# RA register map
Vendor: Renesas; Series: All Chips; File version: x.xx
Registers are 32-bit, read-write, reset 0x0 unless marked. A register's access mark holds for its fields unless they carry their own. Offsets are from the block's base; [hi:lo] are bit positions; 'fields as' and 'values as' point back to an identical list.

## R_CAC — Clock Frequency Accuracy Measurement Circuit
Base 0x40044600
0x00 CACR0 8-bit — CAC Control Register 0
  [0] CFME — Clock Frequency Measurement Enable.
    0=Disable; 1=Enable
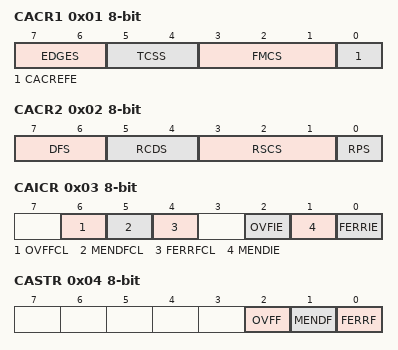
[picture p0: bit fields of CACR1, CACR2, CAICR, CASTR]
0x01 CACR1 8-bit — CAC Control Register 1
  [7:6] EDGES — Valid Edge Select
    0=Rising edge; 1=Falling edge; 2=Both rising and falling edges; 3=Setting prohibited
  [5:4] TCSS — Measurement Target Clock Frequency Division Ratio Select
    0=No division; 1=x 1/4 clock; 2=x 1/8 clock; 3=x 1/32 clock
  [3:1] FMCS — Measurement Target Clock Select
    0=Main clock; 1=Sub-clock; 2=HOCO clock; 3=MOCO clock; 4=LOCO clock; 5=Peripheral module clock(PCLKB); 6=IWDTCLK clock; 7=Setting prohibited
  [0] CACREFE — CACREF Pin Input Enable
    0=Disable; 1=Enable
0x02 CACR2 8-bit — CAC Control Register 2
  [7:6] DFS — Digital Filter Selection
    0=Digital filtering is disabled; 1=The sampling clock for the digital filter is the frequency measuring clock; 2=The sampling clock for the digital filter is the frequency measuring clock divided by 4; 3=The sampling clock for the digital filter is the frequency measuring clock divided by 16
  [5:4] RCDS — Measurement Reference Clock Frequency Division Ratio Select
    0=1/32 clock; 1=1/128 clock; 2=1/1024 clock; 3=1/8192 clock
  [3:1] RSCS — Measurement Reference Clock Select
    values as CACR1.FMCS
  [0] RPS — Reference Signal Select
    0=CACREF pin input; 1=Internal clock (internally generated signal)
0x03 CAICR 8-bit — CAC Interrupt Control Register
  [6] OVFFCL wo — OVFF Clear
    0=No effect on operations; 1=Clears the OVFF flag
  [5] MENDFCL wo — MENDF Clear
    0=No effect on operations; 1=Clears the MENDF flag
  [4] FERRFCL wo — FERRF Clear
    0=No effect on operations; 1=Clears the FERRF flag
  [2] OVFIE — Overflow Interrupt Request Enable
    0=Disable; 1=Enable
  [1] MENDIE — Measurement End Interrupt Request Enable
    0=Disable; 1=Enable
  [0] FERRIE — Frequency Error Interrupt Request Enable
    0=Disable; 1=Enable
0x04 CASTR 8-bit ro — CAC Status Register
  [2] OVFF — Counter Overflow Flag
    0=The counter has not overflowed; 1=The counter has overflowed
  [1] MENDF — Measurement End Flag
    0=Measurement is in progress; 1=Measurement has ended
  [0] FERRF — Frequency Error Flag
    0=The clock frequency is within the range corresponding to the settings; 1=The clock frequency has deviated beyond the range corresponding to the settings (frequency error)
0x06 CAULVR 16-bit — CAC Upper-Limit Value Setting Register
  [15:0] CAULVR — CAULVR is a 16-bit readable/writable register that stores the upper-limit value of the frequency.
0x08 CALLVR 16-bit — CAC Lower-Limit Value Setting Register
  [15:0] CALLVR — CALLVR is a 16-bit readable/writable register that stores the lower-limit value of the frequency.
0x0A CACNTBR 16-bit ro — CAC Counter Buffer Register
  [15:0] CACNTBR — CACNTBR is a 16-bit read-only register that retains the counter value at the time a valid reference signal edge is input

## R_CRC — Cyclic Redundancy Check (CRC) Calculator
Base 0x40074000
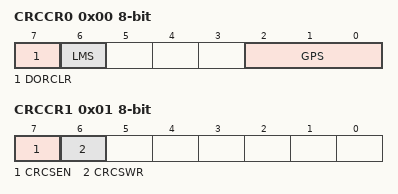
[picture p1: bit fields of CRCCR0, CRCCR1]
0x00 CRCCR0 8-bit — CRC Control Register0
  [7] DORCLR wo — CRCDOR Register Clear
    0=No effect; 1=Clears the CRCDOR register
  [6] LMS — CRC Calculation Switching
    0=Generates CRC for LSB first communication; 1=Generates CRC for MSB first communication
  [2:0] GPS — CRC Generating Polynomial Switching
    0=No calculation is executed; 1=8-bit CRC-8 (X8 + X2 + X + 1); 2=16-bit CRC-16 (X16 + X15 + X2 + 1); 3=16-bit CRC-CCITT (X16 + X12 + X5 + 1); 4=32-bit CRC-32 (X32+X26+X23+X22+X16+X12+X11+X10+X8+X7+X5+X4+X2+X+1); 5=32-bit CRC-32C (X32+X28+X27+X26+ X25+X23+X22+X20+X19+X18+X14+X13+X11+X10+X9+X8+X6+1); other=others (No calculation is executed.)
0x01 CRCCR1 8-bit — CRC Control Register1
  [7] CRCSEN — Snoop enable bit
    0=Disabled; 1=Enabled
  [6] CRCSWR — Snoop-on-write/read switch bit
    0=Snoop-on-read; 1=Snoop-on-write
0x04 CRCDIR — CRC Data Input Register
  [31:0] CRCDIR — Calculation input Data (Case of CRC-32, CRC-32C )
0x04 CRCDIR_BY 8-bit (alternate view of CRCDIR) — CRC Data Input Register (byte access)
  [7:0] CRCDIR_BY — Calculation input Data ( Case of CRC-8, CRC-16 or CRC-CCITT )
0x08 CRCDOR — CRC Data Output Register
  [31:0] CRCDOR — Calculation output Data (Case of CRC-32, CRC-32C )
0x08 CRCDOR_HA 16-bit (alternate view of CRCDOR) — CRC Data Output Register (halfword access)
  [15:0] CRCDOR_HA — Calculation output Data (Case of CRC-16 or CRC-CCITT )
0x08 CRCDOR_BY 8-bit (alternate view of CRCDOR) — CRC Data Output Register(byte access)
  [7:0] CRCDOR_BY — Calculation output Data (Case of CRC-8 )
0x0C CRCSAR 16-bit — Snoop Address Register
  [13:0] CRCSA — snoop address bitSet the I/O register address to snoop
    3=SCI0.TDR; 5=SCI0.RDR; 35=SCI1.TDR; 37=SCI1.RDR; 67=SCI2.TDR; 69=SCI2.RDR; 99=SCI3.TDR; 101=SCI3.RDR; 131=SCI4.TDR; 133=SCI4.RDR; 163=SCI5.TDR; 165=SCI5.RDR; 195=SCI6.TDR; 197=SCI6.RDR; 227=SCI7.TDR; 229=SCI7.RDR; 0x103=SCI8.TDR; 0x105=SCI8.RDR; 0x123=SCI9.TDR; 0x125=SCI9.RDR; other=others (Settings other than above are prohibited.)
